VERSION ""

NS_ :

BS_:

BU_:

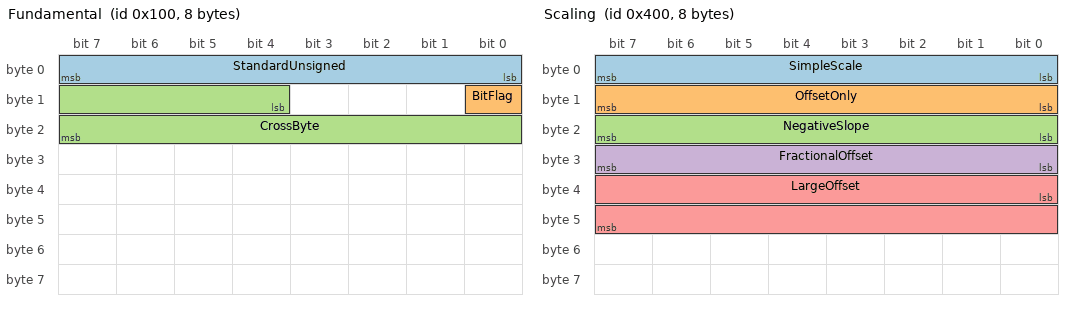
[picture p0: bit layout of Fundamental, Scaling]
BO_ 256 Fundamental: 8 Vector__XXX
 SG_ StandardUnsigned : 0|8@1+ (1,0) [0|0] "" Vector__XXX
 SG_ BitFlag : 8|1@1+ (1,0) [0|0] "" Vector__XXX
 SG_ CrossByte : 12|12@1+ (1,0) [0|0] "" Vector__XXX

BO_ 512 Endianness: 8 Vector__XXX
 SG_ Intel16 : 0|16@1+ (1,0) [0|0] "" Vector__XXX
 SG_ Motorola16 : 23|16@0+ (1,0) [0|0] "" Vector__XXX

BO_ 768 Signed: 8 Vector__XXX
 SG_ Signed8 : 0|8@1- (1,0) [0|0] "" Vector__XXX
 SG_ Signed16 : 8|16@1- (1,0) [0|0] "" Vector__XXX

BO_ 1024 Scaling: 8 Vector__XXX
 SG_ SimpleScale : 0|8@1+ (0.5,0) [0|0] "" Vector__XXX
 SG_ OffsetOnly : 8|8@1+ (1,-40) [0|0] "" Vector__XXX
 SG_ NegativeSlope : 16|8@1+ (-1,100) [0|0] "" Vector__XXX
 SG_ FractionalOffset : 24|8@1+ (0.1,10.5) [0|0] "" Vector__XXX
 SG_ LargeOffset : 32|16@1+ (1,-20000) [0|0] "" Vector__XXX

BO_ 1280 CornerCases: 8 Vector__XXX
 SG_ GapS1 : 0|4@1+ (1,0) [0|0] "" Vector__XXX
 SG_ GapS2 : 5|3@1+ (1,0) [0|0] "" Vector__XXX
